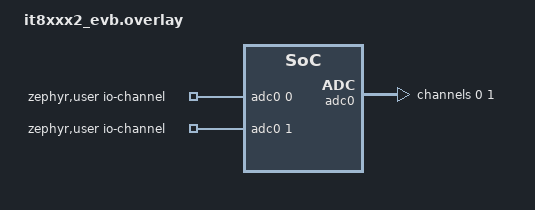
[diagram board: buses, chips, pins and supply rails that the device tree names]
/*
 * SPDX-License-Identifier: Apache-2.0
 *
 * Copyright (c) 2023 Benjamin Björnsson <benjamin.bjornsson@gmail.com>
 */

/ {
	zephyr,user {
		io-channels = <&adc0 0>, <&adc0 1>;
	};
};

&adc0 {
	#address-cells = <1>;
	#size-cells = <0>;
	status = "okay";

	channel@0 {
		reg = <0>;
		zephyr,gain = "ADC_GAIN_1";
		zephyr,reference = "ADC_REF_INTERNAL";
		zephyr,acquisition-time = <ADC_ACQ_TIME_DEFAULT>;
		zephyr,resolution = <10>;
	};

	channel@1 {
		reg = <1>;
		zephyr,gain = "ADC_GAIN_1";
		zephyr,reference = "ADC_REF_INTERNAL";
		zephyr,acquisition-time = <ADC_ACQ_TIME_DEFAULT>;
		zephyr,resolution = <10>;
	};
};
